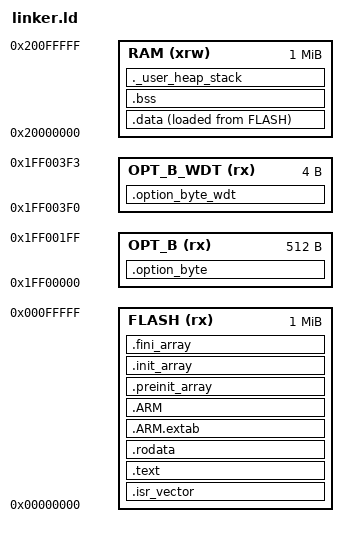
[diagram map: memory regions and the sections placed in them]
/*********************************************************************************************************//**
 * @file    linker.ld
 * @version V1.01
 * @date    2025-03-20
 * @brief   The GNU linker script of HT32 Series.
 *************************************************************************************************************
 * @attention
 *
 * Firmware Disclaimer Information
 *
 * 1. The customer hereby acknowledges and agrees that the program technical documentation, including the
 *    code, which is supplied by Holtek Semiconductor Inc., (hereinafter referred to as "HOLTEK") is the
 *    proprietary and confidential intellectual property of HOLTEK, and is protected by copyright law and
 *    other intellectual property laws.
 *
 * 2. The customer hereby acknowledges and agrees that the program technical documentation, including the
 *    code, is confidential information belonging to HOLTEK, and must not be disclosed to any third parties
 *    other than HOLTEK and the customer.
 *
 * 3. The program technical documentation, including the code, is provided "as is" and for customer reference
 *    only. After delivery by HOLTEK, the customer shall use the program technical documentation, including
 *    the code, at their own risk. HOLTEK disclaims any expressed, implied or statutory warranties, including
 *    the warranties of merchantability, satisfactory quality and fitness for a particular purpose.
 *
 * <h2><center>Copyright (C) Holtek Semiconductor Inc. All rights reserved</center></h2>
 ************************************************************************************************************/

/* Entry Point */
ENTRY(Reset_Handler)

/* Specify the memory areas */
MEMORY
{
FLASH (rx)     : ORIGIN = 0x00000000, LENGTH = 1024K
RAM (xrw)      : ORIGIN = 0x20000000, LENGTH = 1024K
OPT_B (rx)     : ORIGIN = 0x1FF00000, LENGTH = 512
OPT_B_WDT (rx) : ORIGIN = 0x1FF003F0, LENGTH = 4
}

/* Define output sections */
SECTIONS
{

  .option_byte :
  {
    . = ALIGN(4);
    KEEP(*(.HT32_OPTIONS))
    . = ALIGN(4);
  } >OPT_B
  
  .option_byte_wdt :
  {
    . = ALIGN(4);
    KEEP(*(.HT32_OPTIONS_WDT))
    . = ALIGN(4);
  } >OPT_B_WDT

  /* The startup code goes first into FLASH */
  .isr_vector :
  {
    . = ALIGN(4);
    KEEP(*(.isr_vector)) /* Startup code */
    . = ALIGN(4);
  } >FLASH

  /* The program code and other data goes into FLASH */
  .text :
  {
    . = ALIGN(4);
    *(.text)           /* .text sections (code) */
    *(.text*)          /* .text* sections (code) */
    *(.glue_7)         /* glue arm to thumb code */
    *(.glue_7t)        /* glue thumb to arm code */
    *(.eh_frame)

    KEEP (*(.init))
    KEEP (*(.fini))

    . = ALIGN(4);
    _etext = .;        /* define a global symbols at end of code */
  } >FLASH

  /* Constant data goes into FLASH */
  .rodata :
  {
    . = ALIGN(4);
    *(.rodata)         /* .rodata sections (constants, strings, etc.) */
    *(.rodata*)        /* .rodata* sections (constants, strings, etc.) */
    . = ALIGN(4);
  } >FLASH

  /* !!! NOTICE !!!
     For older ARM GNU Toolchain,
     use linker_oldversion.ld to fix "non constant or forward reference address expression for section .XXX" errors.
  */
  .ARM.extab (READONLY) : { *(.ARM.extab* .gnu.linkonce.armextab.*) } >FLASH
  .ARM (READONLY) : {
    __exidx_start = .;
    *(.ARM.exidx*)
    __exidx_end = .;
  } >FLASH

  .preinit_array (READONLY) :
  {
    PROVIDE_HIDDEN (__preinit_array_start = .);
    KEEP (*(.preinit_array*))
    PROVIDE_HIDDEN (__preinit_array_end = .);
  } >FLASH
  .init_array (READONLY) :
  {
    PROVIDE_HIDDEN (__init_array_start = .);
    KEEP (*(SORT(.init_array.*)))
    KEEP (*(.init_array*))
    PROVIDE_HIDDEN (__init_array_end = .);
  } >FLASH
  .fini_array (READONLY) :
  {
    PROVIDE_HIDDEN (__fini_array_start = .);
    KEEP (*(SORT(.fini_array.*)))
    KEEP (*(.fini_array*))
    PROVIDE_HIDDEN (__fini_array_end = .);
  } >FLASH

  /* used by the startup to initialize data */
  _sidata = LOADADDR(.data);

  /* Initialized data sections goes into RAM, load LMA copy after code */
  .data :
  {
    . = ALIGN(4);
    _sdata = .;        /* create a global symbol at data start */
    *(.data)           /* .data sections */
    *(.data*)          /* .data* sections */

    . = ALIGN(4);
    _edata = .;        /* define a global symbol at data end */
  } >RAM AT> FLASH


  /* Uninitialized data section */
  . = ALIGN(4);
  .bss :
  {
    /* This is used by the startup in order to initialize the .bss secion */
    _sbss = .;         /* define a global symbol at bss start */
    __bss_start__ = _sbss;
    *(.bss)
    *(.bss*)
    *(COMMON)

    . = ALIGN(4);
    _ebss = .;         /* define a global symbol at bss end */
    __bss_end__ = _ebss;
  } >RAM

  ._user_heap_stack :
  {
    *(.heap)
    *(.stack)
    . = ALIGN(8);
  } >RAM

  /* Remove information from the standard libraries */
  /DISCARD/ :
  {
    libc.a ( * )
    libm.a ( * )
    libgcc.a ( * )
  }

  .ARM.attributes 0 : { *(.ARM.attributes) }
}
